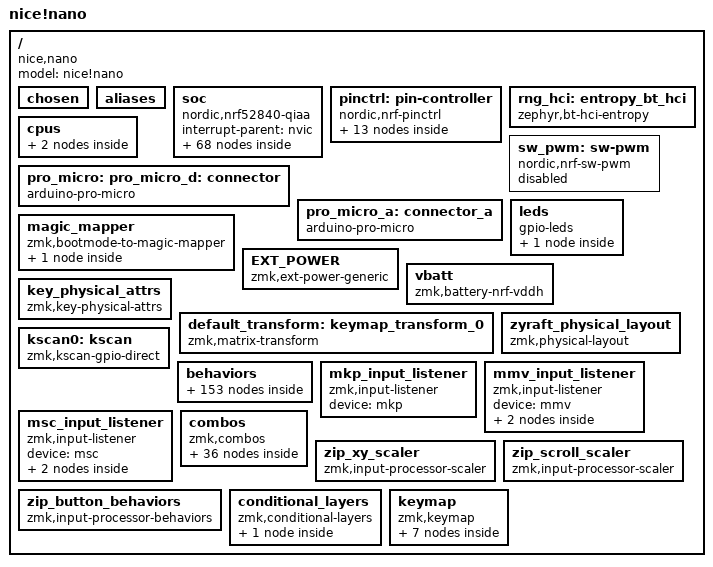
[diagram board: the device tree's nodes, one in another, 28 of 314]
/dts-v1/;

/ {
	#address-cells = < 0x1 >;
	#size-cells = < 0x1 >;
	model = "nice!nano";
	compatible = "nice,nano";
	chosen {
		zephyr,bt-hci = &bt_hci_controller;
		zephyr,entropy = &rng;
		zephyr,flash-controller = &flash_controller;
		zephyr,code-partition = &code_partition;
		zephyr,sram = &sram0;
		zephyr,flash = &flash0;
		zephyr,boot-mode = &boot_retention;
		zmk,magic-boot-mode = &adafruit_boot_retention;
		zmk,battery = &vbatt;
		zmk,physical-layout = &zyraft_physical_layout;
		zmk,kscan = &kscan0;
	};
	aliases {
	};
	soc {
		#address-cells = < 0x1 >;
		#size-cells = < 0x1 >;
		compatible = "nordic,nrf52840-qiaa", "nordic,nrf52840", "nordic,nrf52", "simple-bus";
		interrupt-parent = < &nvic >;
		ranges;
		nvic: interrupt-controller@e000e100 {
			#address-cells = < 0x1 >;
			compatible = "arm,v7m-nvic";
			reg = < 0xe000e100 0xc00 >;
			interrupt-controller;
			#interrupt-cells = < 0x2 >;
			arm,num-irq-priority-bits = < 0x3 >;
			phandle = < 0x1 >;
		};
		systick: timer@e000e010 {
			compatible = "arm,armv7m-systick";
			reg = < 0xe000e010 0x10 >;
			status = "disabled";
		};
		ficr: ficr@10000000 {
			compatible = "nordic,nrf-ficr";
			reg = < 0x10000000 0x1000 >;
			#nordic,ficr-cells = < 0x1 >;
			status = "okay";
		};
		uicr: uicr@10001000 {
			compatible = "nordic,nrf-uicr";
			reg = < 0x10001000 0x1000 >;
			status = "okay";
		};
		sram0: memory@20000000 {
			compatible = "mmio-sram";
			reg = < 0x20000000 0x40000 >;
		};
		clock: clock@40000000 {
			compatible = "nordic,nrf-clock";
			reg = < 0x40000000 0x1000 >;
			interrupts = < 0x0 0x1 >;
			status = "okay";
		};
		power: power@40000000 {
			compatible = "nordic,nrf-power";
			reg = < 0x40000000 0x1000 >;
			interrupts = < 0x0 0x1 >;
			status = "okay";
			#address-cells = < 0x1 >;
			#size-cells = < 0x1 >;
			gpregret1: gpregret1@4000051c {
				#address-cells = < 0x1 >;
				#size-cells = < 0x1 >;
				compatible = "nordic,nrf-gpregret";
				reg = < 0x4000051c 0x1 >;
				status = "okay";
				adafruit_boot_retention: retention@0 {
					compatible = "zephyr,retention";
					status = "okay";
					reg = < 0x0 0x1 >;
				};
			};
			gpregret2: gpregret2@40000520 {
				#address-cells = < 0x1 >;
				#size-cells = < 0x1 >;
				compatible = "nordic,nrf-gpregret";
				reg = < 0x40000520 0x1 >;
				status = "okay";
			};
			reg1: regulator@40000578 {
				compatible = "nordic,nrf5x-regulator";
				reg = < 0x40000578 0x1 >;
				regulator-name = "REG1";
				regulator-initial-mode = < 0x1 >;
			};
			reg0: regulator@40000580 {
				compatible = "nordic,nrf52x-regulator-hv";
				reg = < 0x40000580 0x1 >;
				regulator-name = "REG0";
				status = "okay";
			};
		};
		radio: radio@40001000 {
			compatible = "nordic,nrf-radio";
			reg = < 0x40001000 0x1000 >;
			interrupts = < 0x1 0x1 >;
			status = "okay";
			ieee802154-supported;
			ble-2mbps-supported;
			ble-coded-phy-supported;
			tx-high-power-supported;
			ieee802154: ieee802154 {
				compatible = "nordic,nrf-ieee802154";
				status = "disabled";
			};
			bt_hci_controller: bt_hci_controller {
				compatible = "zephyr,bt-hci-ll-sw-split";
				status = "okay";
			};
		};
		uart0: pro_micro_serial: uart@40002000 {
			compatible = "nordic,nrf-uarte";
			reg = < 0x40002000 0x1000 >;
			interrupts = < 0x2 0x1 >;
			status = "disabled";
			current-speed = < 0x1c200 >;
			pinctrl-0 = < &uart0_default >;
			pinctrl-1 = < &uart0_sleep >;
			pinctrl-names = "default", "sleep";
		};
		i2c0: pro_micro_i2c: i2c@40003000 {
			compatible = "nordic,nrf-twi";
			#address-cells = < 0x1 >;
			#size-cells = < 0x0 >;
			reg = < 0x40003000 0x1000 >;
			interrupts = < 0x3 0x1 >;
			easydma-maxcnt-bits = < 0x10 >;
			status = "disabled";
			zephyr,pm-device-runtime-auto;
			pinctrl-0 = < &i2c0_default >;
			pinctrl-1 = < &i2c0_sleep >;
			pinctrl-names = "default", "sleep";
		};
		spi0: spi@40003000 {
			compatible = "nordic,nrf-spim";
			#address-cells = < 0x1 >;
			#size-cells = < 0x0 >;
			reg = < 0x40003000 0x1000 >;
			interrupts = < 0x3 0x1 >;
			max-frequency = < 0x7a1200 >;
			easydma-maxcnt-bits = < 0x10 >;
			status = "disabled";
		};
		i2c1: i2c@40004000 {
			compatible = "nordic,nrf-twim";
			#address-cells = < 0x1 >;
			#size-cells = < 0x0 >;
			reg = < 0x40004000 0x1000 >;
			interrupts = < 0x4 0x1 >;
			easydma-maxcnt-bits = < 0x10 >;
			status = "disabled";
			zephyr,pm-device-runtime-auto;
		};
		spi1: pro_micro_spi: spi@40004000 {
			compatible = "nordic,nrf-spim";
			#address-cells = < 0x1 >;
			#size-cells = < 0x0 >;
			reg = < 0x40004000 0x1000 >;
			interrupts = < 0x4 0x1 >;
			max-frequency = < 0x7a1200 >;
			easydma-maxcnt-bits = < 0x10 >;
			status = "disabled";
			pinctrl-0 = < &spi1_default >;
			pinctrl-1 = < &spi1_sleep >;
			pinctrl-names = "default", "sleep";
		};
		nfct: nfct@40005000 {
			compatible = "nordic,nrf-nfct";
			reg = < 0x40005000 0x1000 >;
			interrupts = < 0x5 0x1 >;
			status = "disabled";
		};
		gpiote: gpiote0: gpiote@40006000 {
			compatible = "nordic,nrf-gpiote";
			reg = < 0x40006000 0x1000 >;
			interrupts = < 0x6 0x5 >;
			status = "okay";
			instance = < 0x0 >;
			phandle = < 0x8 >;
		};
		adc: adc@40007000 {
			compatible = "nordic,nrf-saadc";
			reg = < 0x40007000 0x1000 >;
			interrupts = < 0x7 0x1 >;
			status = "okay";
			#io-channel-cells = < 0x1 >;
			zephyr,pm-device-runtime-auto;
		};
		timer0: timer@40008000 {
			compatible = "nordic,nrf-timer";
			status = "disabled";
			reg = < 0x40008000 0x1000 >;
			cc-num = < 0x4 >;
			max-bit-width = < 0x20 >;
			interrupts = < 0x8 0x1 >;
			prescaler = < 0x0 >;
		};
		timer1: timer@40009000 {
			compatible = "nordic,nrf-timer";
			status = "disabled";
			reg = < 0x40009000 0x1000 >;
			cc-num = < 0x4 >;
			max-bit-width = < 0x20 >;
			interrupts = < 0x9 0x1 >;
			prescaler = < 0x0 >;
			phandle = < 0x9 >;
		};
		timer2: timer@4000a000 {
			compatible = "nordic,nrf-timer";
			status = "disabled";
			reg = < 0x4000a000 0x1000 >;
			cc-num = < 0x4 >;
			max-bit-width = < 0x20 >;
			interrupts = < 0xa 0x1 >;
			prescaler = < 0x0 >;
		};
		rtc0: rtc@4000b000 {
			compatible = "nordic,nrf-rtc";
			reg = < 0x4000b000 0x1000 >;
			cc-num = < 0x3 >;
			interrupts = < 0xb 0x1 >;
			status = "disabled";
			clock-frequency = < 0x8000 >;
			prescaler = < 0x1 >;
		};
		temp: temp@4000c000 {
			compatible = "nordic,nrf-temp";
			reg = < 0x4000c000 0x1000 >;
			interrupts = < 0xc 0x1 >;
			status = "okay";
		};
		rng: random@4000d000 {
			compatible = "nordic,nrf-rng";
			reg = < 0x4000d000 0x1000 >;
			interrupts = < 0xd 0x1 >;
			status = "okay";
		};
		ecb: ecb@4000e000 {
			compatible = "nordic,nrf-ecb";
			reg = < 0x4000e000 0x1000 >;
			interrupts = < 0xe 0x1 >;
			status = "okay";
		};
		ccm: ccm@4000f000 {
			compatible = "nordic,nrf-ccm";
			reg = < 0x4000f000 0x1000 >;
			interrupts = < 0xf 0x1 >;
			length-field-length-8-bits;
			status = "okay";
		};
		wdt: wdt0: watchdog@40010000 {
			compatible = "nordic,nrf-wdt";
			reg = < 0x40010000 0x1000 >;
			interrupts = < 0x10 0x1 >;
			status = "okay";
		};
		rtc1: rtc@40011000 {
			compatible = "nordic,nrf-rtc";
			reg = < 0x40011000 0x1000 >;
			cc-num = < 0x4 >;
			interrupts = < 0x11 0x1 >;
			status = "disabled";
			clock-frequency = < 0x8000 >;
			prescaler = < 0x1 >;
		};
		qdec: qdec0: qdec@40012000 {
			compatible = "nordic,nrf-qdec";
			reg = < 0x40012000 0x1000 >;
			interrupts = < 0x12 0x1 >;
			status = "disabled";
		};
		comp: comparator@40013000 {
			compatible = "nordic,nrf-comp";
			reg = < 0x40013000 0x1000 >;
			interrupts = < 0x13 0x1 >;
			status = "disabled";
		};
		egu0: swi0: egu@40014000 {
			compatible = "nordic,nrf-egu", "nordic,nrf-swi";
			reg = < 0x40014000 0x1000 >;
			interrupts = < 0x14 0x1 >;
			status = "okay";
		};
		egu1: swi1: egu@40015000 {
			compatible = "nordic,nrf-egu", "nordic,nrf-swi";
			reg = < 0x40015000 0x1000 >;
			interrupts = < 0x15 0x1 >;
			status = "okay";
		};
		egu2: swi2: egu@40016000 {
			compatible = "nordic,nrf-egu", "nordic,nrf-swi";
			reg = < 0x40016000 0x1000 >;
			interrupts = < 0x16 0x1 >;
			status = "okay";
		};
		egu3: swi3: egu@40017000 {
			compatible = "nordic,nrf-egu", "nordic,nrf-swi";
			reg = < 0x40017000 0x1000 >;
			interrupts = < 0x17 0x1 >;
			status = "okay";
		};
		egu4: swi4: egu@40018000 {
			compatible = "nordic,nrf-egu", "nordic,nrf-swi";
			reg = < 0x40018000 0x1000 >;
			interrupts = < 0x18 0x1 >;
			status = "okay";
		};
		egu5: swi5: egu@40019000 {
			compatible = "nordic,nrf-egu", "nordic,nrf-swi";
			reg = < 0x40019000 0x1000 >;
			interrupts = < 0x19 0x1 >;
			status = "okay";
		};
		timer3: timer@4001a000 {
			compatible = "nordic,nrf-timer";
			status = "disabled";
			reg = < 0x4001a000 0x1000 >;
			cc-num = < 0x6 >;
			max-bit-width = < 0x20 >;
			interrupts = < 0x1a 0x1 >;
			prescaler = < 0x0 >;
		};
		timer4: timer@4001b000 {
			compatible = "nordic,nrf-timer";
			status = "disabled";
			reg = < 0x4001b000 0x1000 >;
			cc-num = < 0x6 >;
			max-bit-width = < 0x20 >;
			interrupts = < 0x1b 0x1 >;
			prescaler = < 0x0 >;
		};
		pwm0: pwm@4001c000 {
			compatible = "nordic,nrf-pwm";
			reg = < 0x4001c000 0x1000 >;
			interrupts = < 0x1c 0x1 >;
			status = "disabled";
			#pwm-cells = < 0x3 >;
		};
		pdm0: pdm@4001d000 {
			compatible = "nordic,nrf-pdm";
			reg = < 0x4001d000 0x1000 >;
			interrupts = < 0x1d 0x1 >;
			status = "disabled";
		};
		acl: acl@4001e000 {
			compatible = "nordic,nrf-acl";
			reg = < 0x4001e000 0x1000 >;
			status = "okay";
		};
		flash_controller: flash-controller@4001e000 {
			compatible = "nordic,nrf52-flash-controller";
			reg = < 0x4001e000 0x1000 >;
			partial-erase;
			#address-cells = < 0x1 >;
			#size-cells = < 0x1 >;
			flash0: flash@0 {
				compatible = "soc-nv-flash";
				erase-block-size = < 0x1000 >;
				write-block-size = < 0x4 >;
				reg = < 0x0 0x100000 >;
				partitions {
					compatible = "fixed-partitions";
					#address-cells = < 0x1 >;
					#size-cells = < 0x1 >;
					sd_partition: partition@0 {
						reg = < 0x0 0x26000 >;
					};
					code_partition: partition@26000 {
						reg = < 0x26000 0xc6000 >;
					};
					storage_partition: partition@ec000 {
						reg = < 0xec000 0x8000 >;
					};
					boot_partition: partition@f4000 {
						reg = < 0xf4000 0xc000 >;
					};
				};
			};
		};
		ppi: ppi@4001f000 {
			compatible = "nordic,nrf-ppi";
			reg = < 0x4001f000 0x1000 >;
			status = "okay";
		};
		mwu: mwu@40020000 {
			compatible = "nordic,nrf-mwu";
			reg = < 0x40020000 0x1000 >;
			status = "okay";
		};
		pwm1: pwm@40021000 {
			compatible = "nordic,nrf-pwm";
			reg = < 0x40021000 0x1000 >;
			interrupts = < 0x21 0x1 >;
			status = "disabled";
			#pwm-cells = < 0x3 >;
		};
		pwm2: pwm@40022000 {
			compatible = "nordic,nrf-pwm";
			reg = < 0x40022000 0x1000 >;
			interrupts = < 0x22 0x1 >;
			status = "disabled";
			#pwm-cells = < 0x3 >;
		};
		spi2: spi@40023000 {
			compatible = "nordic,nrf-spim";
			#address-cells = < 0x1 >;
			#size-cells = < 0x0 >;
			reg = < 0x40023000 0x1000 >;
			interrupts = < 0x23 0x1 >;
			max-frequency = < 0x7a1200 >;
			easydma-maxcnt-bits = < 0x10 >;
			status = "disabled";
		};
		rtc2: rtc@40024000 {
			compatible = "nordic,nrf-rtc";
			reg = < 0x40024000 0x1000 >;
			cc-num = < 0x4 >;
			interrupts = < 0x24 0x1 >;
			status = "disabled";
			clock-frequency = < 0x8000 >;
			prescaler = < 0x1 >;
		};
		i2s0: i2s@40025000 {
			compatible = "nordic,nrf-i2s";
			#address-cells = < 0x1 >;
			#size-cells = < 0x0 >;
			reg = < 0x40025000 0x1000 >;
			interrupts = < 0x25 0x1 >;
			status = "disabled";
		};
		usbd: zephyr_udc0: usbd@40027000 {
			compatible = "nordic,nrf-usbd";
			reg = < 0x40027000 0x1000 >;
			interrupts = < 0x27 0x1 >;
			num-bidir-endpoints = < 0x1 >;
			num-in-endpoints = < 0x7 >;
			num-out-endpoints = < 0x7 >;
			num-isoin-endpoints = < 0x1 >;
			num-isoout-endpoints = < 0x1 >;
			status = "okay";
		};
		uart1: uart@40028000 {
			compatible = "nordic,nrf-uarte";
			reg = < 0x40028000 0x1000 >;
			interrupts = < 0x28 0x1 >;
			status = "disabled";
		};
		qspi: qspi@40029000 {
			compatible = "nordic,nrf-qspi";
			#address-cells = < 0x1 >;
			#size-cells = < 0x0 >;
			reg = < 0x40029000 0x1000 >, < 0x12000000 0x8000000 >;
			reg-names = "qspi", "qspi_mm";
			interrupts = < 0x29 0x1 >;
			status = "disabled";
		};
		pwm3: pwm@4002d000 {
			compatible = "nordic,nrf-pwm";
			reg = < 0x4002d000 0x1000 >;
			interrupts = < 0x2d 0x1 >;
			status = "disabled";
			#pwm-cells = < 0x3 >;
		};
		spi3: spi@4002f000 {
			compatible = "nordic,nrf-spim";
			#address-cells = < 0x1 >;
			#size-cells = < 0x0 >;
			reg = < 0x4002f000 0x1000 >;
			interrupts = < 0x2f 0x1 >;
			max-frequency = < 0x1e84800 >;
			easydma-maxcnt-bits = < 0x10 >;
			rx-delay-supported;
			rx-delay = < 0x2 >;
			status = "disabled";
		};
		gpio0: gpio@50000000 {
			compatible = "nordic,nrf-gpio";
			gpio-controller;
			reg = < 0x50000000 0x200 0x50000500 0x300 >;
			#gpio-cells = < 0x2 >;
			status = "okay";
			port = < 0x0 >;
			gpiote-instance = < &gpiote >;
			phandle = < 0xa >;
		};
		gpio1: gpio@50000300 {
			compatible = "nordic,nrf-gpio";
			gpio-controller;
			reg = < 0x50000300 0x200 0x50000800 0x300 >;
			#gpio-cells = < 0x2 >;
			ngpios = < 0x10 >;
			status = "okay";
			port = < 0x1 >;
			gpiote-instance = < &gpiote >;
			phandle = < 0xb >;
		};
		cryptocell: crypto@5002a000 {
			compatible = "nordic,cryptocell", "arm,cryptocell-310";
			reg = < 0x5002a000 0x1000 >, < 0x5002b000 0x1000 >;
			reg-names = "wrapper", "core";
			interrupts = < 0x2a 0x1 >;
			status = "disabled";
		};
	};
	pinctrl: pin-controller {
		compatible = "nordic,nrf-pinctrl";
		uart0_default: uart0_default {
			phandle = < 0x2 >;
			group1 {
				psels = < 0x1000008 >;
				bias-pull-up;
			};
			group2 {
				psels = < 0x6 >;
			};
		};
		uart0_sleep: uart0_sleep {
			phandle = < 0x3 >;
			group1 {
				psels = < 0x1000008 >, < 0x6 >;
				low-power-enable;
			};
		};
		i2c0_default: i2c0_default {
			phandle = < 0x4 >;
			group1 {
				psels = < 0xc000011 >, < 0xb000014 >;
			};
		};
		i2c0_sleep: i2c0_sleep {
			phandle = < 0x5 >;
			group1 {
				psels = < 0xc000011 >, < 0xb000014 >;
				low-power-enable;
			};
		};
		spi1_default: spi1_default {
			phandle = < 0x6 >;
			group1 {
				psels = < 0x400002d >, < 0x500000a >, < 0x600002b >;
			};
		};
		spi1_sleep: spi1_sleep {
			phandle = < 0x7 >;
			group1 {
				psels = < 0x400002d >, < 0x500000a >, < 0x600002b >;
				low-power-enable;
			};
		};
	};
	rng_hci: entropy_bt_hci {
		compatible = "zephyr,bt-hci-entropy";
		status = "okay";
	};
	sw_pwm: sw-pwm {
		compatible = "nordic,nrf-sw-pwm";
		status = "disabled";
		generator = < &timer1 >;
		clock-prescaler = < 0x0 >;
		#pwm-cells = < 0x3 >;
	};
	cpus {
		#address-cells = < 0x1 >;
		#size-cells = < 0x0 >;
		cpu@0 {
			device_type = "cpu";
			compatible = "arm,cortex-m4f";
			reg = < 0x0 >;
			#address-cells = < 0x1 >;
			#size-cells = < 0x1 >;
			itm: itm@e0000000 {
				compatible = "arm,armv7m-itm";
				reg = < 0xe0000000 0x1000 >;
				swo-ref-frequency = < 0x1e84800 >;
			};
		};
	};
	pro_micro: pro_micro_d: connector {
		compatible = "arduino-pro-micro";
		#gpio-cells = < 0x2 >;
		gpio-map-mask = < 0xffffffff 0xffffffc0 >;
		gpio-map-pass-thru = < 0x0 0x3f >;
		gpio-map = < 0x0 0x0 &gpio0 0x8 0x0 >, < 0x1 0x0 &gpio0 0x6 0x0 >, < 0x2 0x0 &gpio0 0x11 0x0 >, < 0x3 0x0 &gpio0 0x14 0x0 >, < 0x4 0x0 &gpio0 0x16 0x0 >, < 0x5 0x0 &gpio0 0x18 0x0 >, < 0x6 0x0 &gpio1 0x0 0x0 >, < 0x7 0x0 &gpio0 0xb 0x0 >, < 0x8 0x0 &gpio1 0x4 0x0 >, < 0x9 0x0 &gpio1 0x6 0x0 >, < 0xa 0x0 &gpio0 0x9 0x0 >, < 0x10 0x0 &gpio0 0xa 0x0 >, < 0xe 0x0 &gpio1 0xb 0x0 >, < 0xf 0x0 &gpio1 0xd 0x0 >, < 0x12 0x0 &gpio1 0xf 0x0 >, < 0x13 0x0 &gpio0 0x2 0x0 >, < 0x14 0x0 &gpio0 0x1d 0x0 >, < 0x15 0x0 &gpio0 0x1f 0x0 >;
		phandle = < 0xe >;
	};
	pro_micro_a: connector_a {
		compatible = "arduino-pro-micro";
		#gpio-cells = < 0x2 >;
		gpio-map-mask = < 0xffffffff 0xffffffc0 >;
		gpio-map-pass-thru = < 0x0 0x3f >;
		gpio-map = < 0x0 0x0 &gpio1 0xf 0x0 >, < 0x1 0x0 &gpio0 0x2 0x0 >, < 0x2 0x0 &gpio0 0x1d 0x0 >, < 0x3 0x0 &gpio0 0x1f 0x0 >, < 0x6 0x0 &gpio0 0x16 0x0 >, < 0x7 0x0 &gpio1 0x0 0x0 >, < 0x8 0x0 &gpio1 0x4 0x0 >, < 0x9 0x0 &gpio1 0x6 0x0 >, < 0xa 0x0 &gpio0 0x9 0x0 >;
	};
	leds {
		compatible = "gpio-leds";
		blue_led: led_0 {
			gpios = < &gpio0 0xf 0x0 >;
		};
	};
	magic_mapper {
		compatible = "zmk,bootmode-to-magic-mapper";
		status = "okay";
		#address-cells = < 0x1 >;
		#size-cells = < 0x1 >;
		boot_retention: retention@0 {
			compatible = "zephyr,retention";
			status = "okay";
			reg = < 0x0 0x1 >;
		};
	};
	EXT_POWER {
		compatible = "zmk,ext-power-generic";
		control-gpios = < &gpio0 0xd 0x0 >;
		init-delay-ms = < 0x32 >;
	};
	vbatt: vbatt {
		compatible = "zmk,battery-nrf-vddh";
	};
	key_physical_attrs: key_physical_attrs {
		compatible = "zmk,key-physical-attrs";
		#key-cells = < 0x7 >;
		phandle = < 0xd >;
	};
	default_transform: keymap_transform_0 {
		compatible = "zmk,matrix-transform";
		columns = < 0x22 >;
		rows = < 0x1 >;
		map = < 0x0 0x1 0x2 0x3 0x4 0x15 0x14 0x13 0x12 0x11 0x5 0x6 0x7 0x8 0x9 0x1a 0x19 0x18 0x17 0x16 0xa 0xb 0xc 0xd 0xe 0x1f 0x1e 0x1d 0x1c 0x1b 0xf 0x10 0x21 0x20 >;
		phandle = < 0xc >;
	};
	zyraft_physical_layout: zyraft_physical_layout {
		compatible = "zmk,physical-layout";
		display-name = "Zyra FT";
		transform = < &default_transform >;
		keys = < &key_physical_attrs 0x64 0x64 0x0 0x5f 0x0 0x0 0x0 >, < &key_physical_attrs 0x64 0x64 0x64 0x20 0x0 0x0 0x0 >, < &key_physical_attrs 0x64 0x64 0xc8 0x0 0x0 0x0 0x0 >, < &key_physical_attrs 0x64 0x64 0x12c 0x1c 0x0 0x0 0x0 >, < &key_physical_attrs 0x64 0x64 0x190 0x2a 0x0 0x0 0x0 >, < &key_physical_attrs 0x64 0x64 0x2bc 0x2a 0x0 0x0 0x0 >, < &key_physical_attrs 0x64 0x64 0x320 0x1c 0x0 0x0 0x0 >, < &key_physical_attrs 0x64 0x64 0x384 0x0 0x0 0x0 0x0 >, < &key_physical_attrs 0x64 0x64 0x3e8 0x20 0x0 0x0 0x0 >, < &key_physical_attrs 0x64 0x64 0x44c 0x5f 0x0 0x0 0x0 >, < &key_physical_attrs 0x64 0x64 0x0 0xc3 0x0 0x0 0x0 >, < &key_physical_attrs 0x64 0x64 0x64 0x84 0x0 0x0 0x0 >, < &key_physical_attrs 0x64 0x64 0xc8 0x64 0x0 0x0 0x0 >, < &key_physical_attrs 0x64 0x64 0x12c 0x80 0x0 0x0 0x0 >, < &key_physical_attrs 0x64 0x64 0x190 0x8e 0x0 0x0 0x0 >, < &key_physical_attrs 0x64 0x64 0x2bc 0x8e 0x0 0x0 0x0 >, < &key_physical_attrs 0x64 0x64 0x320 0x80 0x0 0x0 0x0 >, < &key_physical_attrs 0x64 0x64 0x384 0x64 0x0 0x0 0x0 >, < &key_physical_attrs 0x64 0x64 0x3e8 0x84 0x0 0x0 0x0 >, < &key_physical_attrs 0x64 0x64 0x44c 0xc3 0x0 0x0 0x0 >, < &key_physical_attrs 0x64 0x64 0x0 0x127 0x0 0x0 0x0 >, < &key_physical_attrs 0x64 0x64 0x64 0xe8 0x0 0x0 0x0 >, < &key_physical_attrs 0x64 0x64 0xc8 0xc8 0x0 0x0 0x0 >, < &key_physical_attrs 0x64 0x64 0x12c 0xe4 0x0 0x0 0x0 >, < &key_physical_attrs 0x64 0x64 0x190 0xf2 0x0 0x0 0x0 >, < &key_physical_attrs 0x64 0x64 0x2bc 0xf2 0x0 0x0 0x0 >, < &key_physical_attrs 0x64 0x64 0x320 0xe4 0x0 0x0 0x0 >, < &key_physical_attrs 0x64 0x64 0x384 0xc8 0x0 0x0 0x0 >, < &key_physical_attrs 0x64 0x64 0x3e8 0xe8 0x0 0x0 0x0 >, < &key_physical_attrs 0x64 0x64 0x44c 0x127 0x0 0x0 0x0 >, < &key_physical_attrs 0x64 0x64 0x12c 0x156 0x0 0x0 0x0 >, < &key_physical_attrs 0x64 0x64 0x190 0x181 0x0 0x0 0x0 >, < &key_physical_attrs 0x64 0x64 0x2bc 0x181 0x0 0x0 0x0 >, < &key_physical_attrs 0x64 0x64 0x320 0x156 0x0 0x0 0x0 >;
	};
	kscan0: kscan {
		compatible = "zmk,kscan-gpio-direct";
		wakeup-source;
		input-gpios = < &pro_micro 0x7 0x11 >, < &pro_micro 0x12 0x11 >, < &pro_micro 0x13 0x11 >, < &pro_micro 0x14 0x11 >, < &pro_micro 0x15 0x11 >, < &pro_micro 0xf 0x11 >, < &pro_micro 0xe 0x11 >, < &pro_micro 0x10 0x11 >, < &pro_micro 0xa 0x11 >, < &pro_micro 0x1 0x11 >, < &pro_micro 0x2 0x11 >, < &pro_micro 0x3 0x11 >, < &pro_micro 0x4 0x11 >, < &pro_micro 0x5 0x11 >, < &pro_micro 0x6 0x11 >, < &pro_micro 0x8 0x11 >, < &pro_micro 0x9 0x11 >;
	};
	behaviors {
		os_sel: os_selector {
			compatible = "zmk,behavior-os-selector";
			#binding-cells = < 0x1 >;
			phandle = < 0x2a >;
		};
		ok_cut: os_key_cut {
			compatible = "zmk,behavior-os-key";
			#binding-cells = < 0x0 >;
			bindings = < &kp 0x107001b >, < &kp 0x807001b >, < &kp 0x107001b >;
			phandle = < 0x38 >;
		};
		ok_copy: os_key_copy {
			compatible = "zmk,behavior-os-key";
			#binding-cells = < 0x0 >;
			bindings = < &kp 0x1070006 >, < &kp 0x8070006 >, < &kp 0x1070006 >;
			phandle = < 0x39 >;
		};
		ok_paste: os_key_paste {
			compatible = "zmk,behavior-os-key";
			#binding-cells = < 0x0 >;
			bindings = < &kp 0x1070019 >, < &kp 0x8070019 >, < &kp 0x1070019 >;
			phandle = < 0x3a >;
		};
		ok_undo: os_key_undo {
			compatible = "zmk,behavior-os-key";
			#binding-cells = < 0x0 >;
			bindings = < &kp 0x107001d >, < &kp 0x807001d >, < &kp 0x107001d >;
			phandle = < 0x4a >;
		};
		ok_redo: os_key_redo {
			compatible = "zmk,behavior-os-key";
			#binding-cells = < 0x0 >;
			bindings = < &kp 0x107001c >, < &kp 0xa07001d >, < &kp 0x307001d >;
			phandle = < 0x4b >;
		};
		ok_sel_all: os_key_select_all {
			compatible = "zmk,behavior-os-key";
			#binding-cells = < 0x0 >;
			bindings = < &kp 0x1070004 >, < &kp 0x8070004 >, < &kp 0x1070004 >;
		};
		ok_find: os_key_find {
			compatible = "zmk,behavior-os-key";
			#binding-cells = < 0x0 >;
			bindings = < &kp 0x1070009 >, < &kp 0x8070009 >, < &kp 0x1070009 >;
		};
		ok_find_replace: os_key_find_replace {
			compatible = "zmk,behavior-os-key";
			#binding-cells = < 0x0 >;
			bindings = < &kp 0x107000b >, < &kp 0x807000b >, < &kp 0x107000b >;
		};
		ok_bold: os_key_bold {
			compatible = "zmk,behavior-os-key";
			#binding-cells = < 0x0 >;
			bindings = < &kp 0x1070005 >, < &kp 0x8070005 >, < &kp 0x1070005 >;
		};
		ok_italic: os_key_italic {
			compatible = "zmk,behavior-os-key";
			#binding-cells = < 0x0 >;
			bindings = < &kp 0x107000c >, < &kp 0x807000c >, < &kp 0x107000c >;
		};
		ok_underline: os_key_underline {
			compatible = "zmk,behavior-os-key";
			#binding-cells = < 0x0 >;
			bindings = < &kp 0x1070018 >, < &kp 0x8070018 >, < &kp 0x1070018 >;
		};
		ok_new_win: os_key_new_window {
			compatible = "zmk,behavior-os-key";
			#binding-cells = < 0x0 >;
			bindings = < &kp 0x1070011 >, < &kp 0x8070011 >, < &kp 0x1070011 >;
		};
		ok_new_tab: os_key_new_tab {
			compatible = "zmk,behavior-os-key";
			#binding-cells = < 0x0 >;
			bindings = < &kp 0x1070017 >, < &kp 0x8070017 >, < &kp 0x1070017 >;
		};
		ok_close: os_key_close {
			compatible = "zmk,behavior-os-key";
			#binding-cells = < 0x0 >;
			bindings = < &kp 0x107001a >, < &kp 0x807001a >, < &kp 0x107001a >;
		};
		ok_quit: os_key_quit {
			compatible = "zmk,behavior-os-key";
			#binding-cells = < 0x0 >;
			bindings = < &kp 0x407003d >, < &kp 0x8070014 >, < &kp 0x407003d >;
		};
		ok_reopen_tab: os_key_reopen_tab {
			compatible = "zmk,behavior-os-key";
			#binding-cells = < 0x0 >;
			bindings = < &kp 0x3070017 >, < &kp 0xa070017 >, < &kp 0x3070017 >;
		};
		ok_open: os_key_open {
			compatible = "zmk,behavior-os-key";
			#binding-cells = < 0x0 >;
			bindings = < &kp 0x1070012 >, < &kp 0x8070012 >, < &kp 0x1070012 >;
		};
		ok_save: os_key_save {
			compatible = "zmk,behavior-os-key";
			#binding-cells = < 0x0 >;
			bindings = < &kp 0x1070016 >, < &kp 0x8070016 >, < &kp 0x1070016 >;
		};
		ok_save_as: os_key_save_as {
			compatible = "zmk,behavior-os-key";
			#binding-cells = < 0x0 >;
			bindings = < &kp 0x3070016 >, < &kp 0xa070016 >, < &kp 0x3070016 >;
		};
		ok_print: os_key_print {
			compatible = "zmk,behavior-os-key";
			#binding-cells = < 0x0 >;
			bindings = < &kp 0x1070013 >, < &kp 0x8070013 >, < &kp 0x1070013 >;
		};
		ok_zoom_in: os_key_zoom_in {
			compatible = "zmk,behavior-os-key";
			#binding-cells = < 0x0 >;
			bindings = < &kp 0x107002e >, < &kp 0x807002e >, < &kp 0x107002e >;
		};
		ok_zoom_out: os_key_zoom_out {
			compatible = "zmk,behavior-os-key";
			#binding-cells = < 0x0 >;
			bindings = < &kp 0x107002d >, < &kp 0x807002d >, < &kp 0x107002d >;
		};
		ok_zoom_reset: os_key_zoom_reset {
			compatible = "zmk,behavior-os-key";
			#binding-cells = < 0x0 >;
			bindings = < &kp 0x1070027 >, < &kp 0x8070027 >, < &kp 0x1070027 >;
		};
		ok_prev_word: os_key_prev_word {
			compatible = "zmk,behavior-os-key";
			#binding-cells = < 0x0 >;
			bindings = < &kp 0x1070050 >, < &kp 0x4070050 >, < &kp 0x1070050 >;
		};
		ok_next_word: os_key_next_word {
			compatible = "zmk,behavior-os-key";
			#binding-cells = < 0x0 >;
			bindings = < &kp 0x107004f >, < &kp 0x407004f >, < &kp 0x107004f >;
		};
		ok_line_start: os_key_line_start {
			compatible = "zmk,behavior-os-key";
			#binding-cells = < 0x0 >;
			bindings = < &kp 0x7004a >, < &kp 0x8070050 >, < &kp 0x7004a >;
		};
		ok_line_end: os_key_line_end {
			compatible = "zmk,behavior-os-key";
			#binding-cells = < 0x0 >;
			bindings = < &kp 0x7004d >, < &kp 0x807004f >, < &kp 0x7004d >;
		};
		ok_doc_start: os_key_doc_start {
			compatible = "zmk,behavior-os-key";
			#binding-cells = < 0x0 >;
			bindings = < &kp 0x107004a >, < &kp 0x8070052 >, < &kp 0x107004a >;
		};
		ok_doc_end: os_key_doc_end {
			compatible = "zmk,behavior-os-key";
			#binding-cells = < 0x0 >;
			bindings = < &kp 0x107004d >, < &kp 0x8070051 >, < &kp 0x107004d >;
		};
		ok_sel_prev_word: os_key_sel_prev_word {
			compatible = "zmk,behavior-os-key";
			#binding-cells = < 0x0 >;
			bindings = < &kp 0x3070050 >, < &kp 0x6070050 >, < &kp 0x3070050 >;
		};
		ok_sel_next_word: os_key_sel_next_word {
			compatible = "zmk,behavior-os-key";
			#binding-cells = < 0x0 >;
			bindings = < &kp 0x307004f >, < &kp 0x607004f >, < &kp 0x307004f >;
		};
		ok_sel_line_start: os_key_sel_line_start {
			compatible = "zmk,behavior-os-key";
			#binding-cells = < 0x0 >;
			bindings = < &kp 0x207004a >, < &kp 0xa070050 >, < &kp 0x207004a >;
		};
		ok_sel_line_end: os_key_sel_line_end {
			compatible = "zmk,behavior-os-key";
			#binding-cells = < 0x0 >;
			bindings = < &kp 0x207004d >, < &kp 0xa07004f >, < &kp 0x207004d >;
		};
		ok_sel_doc_start: os_key_sel_doc_start {
			compatible = "zmk,behavior-os-key";
			#binding-cells = < 0x0 >;
			bindings = < &kp 0x307004a >, < &kp 0xa070052 >, < &kp 0x307004a >;
		};
		ok_sel_doc_end: os_key_sel_doc_end {
			compatible = "zmk,behavior-os-key";
			#binding-cells = < 0x0 >;
			bindings = < &kp 0x307004d >, < &kp 0xa070051 >, < &kp 0x307004d >;
		};
		ok_ltm: os_layer_mod {
			compatible = "zmk,behavior-os-layer-mod";
			#binding-cells = < 0x2 >;
			tapping-term-ms = < 0xc8 >;
			bindings = < &kp 0x700e2 >, < &kp 0x700e3 >, < &kp 0x700e3 >;
		};
		ok_next_app: os_key_next_app {
			compatible = "zmk,behavior-os-key";
			#binding-cells = < 0x0 >;
			bindings = < &kp 0x407002b >, < &kp 0x807002b >, < &kp 0x807002b >;
		};
		ok_prev_app: os_key_prev_app {
			compatible = "zmk,behavior-os-key";
			#binding-cells = < 0x0 >;
			bindings = < &kp 0x607002b >, < &kp 0xa07002b >, < &kp 0xa07002b >;
		};
		ok_next_tab: os_key_next_tab {
			compatible = "zmk,behavior-os-key";
			#binding-cells = < 0x0 >;
			bindings = < &kp 0x3070030 >, < &kp 0xa070030 >, < &kp 0x107004e >;
		};
		ok_prev_tab: os_key_prev_tab {
			compatible = "zmk,behavior-os-key";
			#binding-cells = < 0x0 >;
			bindings = < &kp 0x307002f >, < &kp 0xa07002f >, < &kp 0x107004b >;
		};
		ok_mission_ctrl: os_key_mission_control {
			compatible = "zmk,behavior-os-key";
			#binding-cells = < 0x0 >;
			bindings = < &kp 0x807002b >, < &kp 0x1070052 >, < &kp 0x700e3 >;
		};
		ok_desktop: os_key_desktop {
			compatible = "zmk,behavior-os-key";
			#binding-cells = < 0x0 >;
			bindings = < &kp 0x8070007 >, < &kp 0x9070007 >, < &kp 0x8070007 >;
		};
		ok_lock: os_key_lock {
			compatible = "zmk,behavior-os-key";
			#binding-cells = < 0x0 >;
			bindings = < &kp 0x807000f >, < &kp 0x9070014 >, < &kp 0x807000f >;
		};
		ok_force_quit: os_key_force_quit {
			compatible = "zmk,behavior-os-key";
			#binding-cells = < 0x0 >;
			bindings = < &kp 0x3070029 >, < &kp 0xc070029 >, < &kp 0x1070029 >;
		};
		kp: key_press {
			compatible = "zmk,behavior-key-press";
			#binding-cells = < 0x1 >;
			display-name = "Key Press";
			phandle = < 0xf >;
		};
		kt: key_toggle {
			compatible = "zmk,behavior-key-toggle";
			#binding-cells = < 0x1 >;
			display-name = "Key Toggle";
			phandle = < 0x2b >;
		};
		trans: transparent {
			compatible = "zmk,behavior-transparent";
			#binding-cells = < 0x0 >;
			display-name = "Transparent";
			phandle = < 0x46 >;
		};
		none: none {
			compatible = "zmk,behavior-none";
			#binding-cells = < 0x0 >;
			display-name = "None";
			phandle = < 0x24 >;
		};
		mt: mod_tap {
			compatible = "zmk,behavior-hold-tap";
			#binding-cells = < 0x2 >;
			flavor = "tap-preferred";
			tapping-term-ms = < 0xdc >;
			bindings = < &kp >, < &kp >;
			display-name = "Mod-Tap";
			quick-tap-ms = < 0xdc >;
			hold-trigger-key-positions = < 0x0 >;
			phandle = < 0x45 >;
		};
		lt: layer_tap {
			compatible = "zmk,behavior-hold-tap";
			#binding-cells = < 0x2 >;
			flavor = "balanced";
			tapping-term-ms = < 0xc8 >;
			bindings = < &mo >, < &kp >;
			display-name = "Layer-Tap";
			quick-tap-ms = < 0xaf >;
			phandle = < 0x3e >;
		};
		sk: sticky_key {
			compatible = "zmk,behavior-sticky-key";
			#binding-cells = < 0x1 >;
			release-after-ms = < 0x384 >;
			bindings = < &kp >;
			ignore-modifiers;
			display-name = "Sticky Key";
			quick-release;
			phandle = < 0x1e >;
		};
		sl: sticky_layer {
			compatible = "zmk,behavior-sticky-key";
			#binding-cells = < 0x1 >;
			release-after-ms = < 0x3e8 >;
			bindings = < &mo >;
			quick-release;
			display-name = "Sticky Layer";
			ignore-modifiers;
			phandle = < 0x22 >;
		};
		mo: momentary_layer {
			compatible = "zmk,behavior-momentary-layer";
			#binding-cells = < 0x1 >;
			display-name = "Momentary Layer";
			phandle = < 0x10 >;
		};
		tog: toggle_layer {
			compatible = "zmk,behavior-toggle-layer";
			#binding-cells = < 0x1 >;
			display-name = "Toggle Layer";
			locking;
			phandle = < 0x23 >;
		};
		sys_reset: sysreset {
			compatible = "zmk,behavior-reset";
			#binding-cells = < 0x0 >;
			display-name = "Reset";
			phandle = < 0x17 >;
		};
		bootloader: bootload {
			compatible = "zmk,behavior-reset";
			type = < 0x57 >;
			bootloader;
			#binding-cells = < 0x0 >;
			display-name = "Bootloader";
			phandle = < 0x18 >;
		};
		rgb_ug: rgb_ug {
			compatible = "zmk,behavior-rgb-underglow";
			#binding-cells = < 0x2 >;
			display-name = "Underglow";
		};
		bt: bluetooth {
			compatible = "zmk,behavior-bluetooth";
			#binding-cells = < 0x2 >;
			display-name = "Bluetooth";
			phandle = < 0x29 >;
		};
		ext_power: extpower {
			compatible = "zmk,behavior-ext-power";
			#binding-cells = < 0x1 >;
			display-name = "External Power";
		};
		out: outputs {
			compatible = "zmk,behavior-outputs";
			#binding-cells = < 0x1 >;
			display-name = "Output Selection";
			phandle = < 0x16 >;
		};
		caps_word: caps_word {
			compatible = "zmk,behavior-caps-word";
			#binding-cells = < 0x0 >;
			continue-list = < 0x207002d 0x7002a 0x7004c >;
			display-name = "Caps Word";
			phandle = < 0x1d >;
		};
		key_repeat: key_repeat {
			compatible = "zmk,behavior-key-repeat";
			#binding-cells = < 0x0 >;
			usage-pages = < 0x7 >;
			display-name = "Key Repeat";
			phandle = < 0x1f >;
		};
		macro_tap: macro_tap {
			compatible = "zmk,macro-control-mode-tap";
			#binding-cells = < 0x0 >;
		};
		macro_press: macro_press {
			compatible = "zmk,macro-control-mode-press";
			#binding-cells = < 0x0 >;
		};
		macro_release: macro_release {
			compatible = "zmk,macro-control-mode-release";
			#binding-cells = < 0x0 >;
		};
		macro_tap_time: macro_tap_time {
			compatible = "zmk,macro-control-tap-time";
			#binding-cells = < 0x1 >;
		};
		macro_wait_time: macro_wait_time {
			compatible = "zmk,macro-control-wait-time";
			#binding-cells = < 0x1 >;
		};
		macro_pause_for_release: macro_pause_for_release {
			compatible = "zmk,macro-pause-for-release";
			#binding-cells = < 0x0 >;
		};
		macro_param_1to1: macro_param_1to1 {
			compatible = "zmk,macro-param-1to1";
			#binding-cells = < 0x0 >;
		};
		macro_param_1to2: macro_param_1to2 {
			compatible = "zmk,macro-param-1to2";
			#binding-cells = < 0x0 >;
		};
		macro_param_2to1: macro_param_2to1 {
			compatible = "zmk,macro-param-2to1";
			#binding-cells = < 0x0 >;
		};
		macro_param_2to2: macro_param_2to2 {
			compatible = "zmk,macro-param-2to2";
			#binding-cells = < 0x0 >;
		};
		studio_unlock: studio_unlock {
			compatible = "zmk,behavior-studio-unlock";
			#binding-cells = < 0x0 >;
			display-name = "Studio Unlock";
			phandle = < 0x4c >;
		};
		mkp: mouse_key_press {
			compatible = "zmk,behavior-mouse-key-press";
			#binding-cells = < 0x1 >;
			display-name = "Mouse Key Press";
			phandle = < 0x2f >;
		};
		mmv: mouse_move {
			compatible = "zmk,behavior-input-two-axis";
			#binding-cells = < 0x1 >;
			x-input-code = < 0x0 >;
			y-input-code = < 0x1 >;
			time-to-max-speed-ms = < 0x1f4 >;
			acceleration-exponent = < 0x1 >;
			delay-ms = < 0x0 >;
			phandle = < 0x30 >;
		};
		msc: mouse_scroll {
			compatible = "zmk,behavior-input-two-axis";
			#binding-cells = < 0x1 >;
			x-input-code = < 0x6 >;
			y-input-code = < 0x8 >;
			time-to-max-speed-ms = < 0x12c >;
			acceleration-exponent = < 0x0 >;
			delay-ms = < 0x0 >;
			phandle = < 0x32 >;
		};
		num_word: num_word {
			compatible = "zmk,behavior-auto-layer";
			#binding-cells = < 0x1 >;
			continue-list = < 0x7002a 0x7004c 0x70037 0x70036 0x207002e 0x7002d 0x2070025 0x70038 0x7002e >;
			ignore-numbers;
			phandle = < 0x21 >;
		};
		mask_mods: mask_mods {
			compatible = "zmk,behavior-mask-mods";
			#binding-cells = < 0x1 >;
			display-name = "Mask Mods";
		};
		uc: unicode {
			compatible = "zmk,behavior-unicode";
			#binding-cells = < 0x2 >;
			display-name = "Unicode input";
			default-mode = < 0x3 >;
			phandle = < 0x15 >;
		};
		hml: hml {
			compatible = "zmk,behavior-hold-tap";
			#binding-cells = < 0x2 >;
			bindings = < &kp >, < &kp >;
			flavor = "balanced";
			tapping-term-ms = < 0x118 >;
			quick-tap-ms = < 0xaf >;
			require-prior-idle-ms = < 0x96 >;
			hold-trigger-on-release;
			hold-trigger-key-positions = < 0x5 0x6 0x7 0x8 0x9 0xf 0x10 0x11 0x12 0x13 0x19 0x1a 0x1b 0x1c 0x1d 0x1e 0x1f 0x20 0x21 >;
			phandle = < 0x35 >;
		};
		hmr: hmr {
			compatible = "zmk,behavior-hold-tap";
			#binding-cells = < 0x2 >;
			bindings = < &kp >, < &kp >;
			flavor = "balanced";
			tapping-term-ms = < 0x118 >;
			quick-tap-ms = < 0xaf >;
			require-prior-idle-ms = < 0x96 >;
			hold-trigger-on-release;
			hold-trigger-key-positions = < 0x4 0x3 0x2 0x1 0x0 0xe 0xd 0xc 0xb 0xa 0x18 0x17 0x16 0x15 0x14 0x1e 0x1f 0x20 0x21 >;
			phandle = < 0x40 >;
		};
		hm_combo_ldr: hm_combo_ldr {
			compatible = "zmk,behavior-hold-tap";
			#binding-cells = < 0x2 >;
			bindings = < &kp >, < &leader >;
			flavor = "balanced";
			tapping-term-ms = < 0x118 >;
			quick-tap-ms = < 0xaf >;
			require-prior-idle-ms = < 0x96 >;
			hold-trigger-on-release;
			hold-trigger-key-positions = < 0x5 0x6 0x7 0x8 0x9 0xf 0x10 0x11 0x12 0x13 0x19 0x1a 0x1b 0x1c 0x1d 0x1e 0x1f 0x20 0x21 >;
			phandle = < 0x36 >;
		};
		hm_combo_ldrsh: hm_combo_ldrsh {
			compatible = "zmk,behavior-hold-tap";
			#binding-cells = < 0x2 >;
			bindings = < &kp >, < &leader_sft >;
			flavor = "balanced";
			tapping-term-ms = < 0x118 >;
			quick-tap-ms = < 0xaf >;
			require-prior-idle-ms = < 0x96 >;
			hold-trigger-on-release;
			hold-trigger-key-positions = < 0x5 0x6 0x7 0x8 0x9 0xf 0x10 0x11 0x12 0x13 0x19 0x1a 0x1b 0x1c 0x1d 0x1e 0x1f 0x20 0x21 >;
			phandle = < 0x37 >;
		};
		hm_combo_lpar: hm_combo_lpar {
			compatible = "zmk,behavior-hold-tap";
			#binding-cells = < 0x2 >;
			bindings = < &kp >, < &lpar_lt >;
			flavor = "balanced";
			tapping-term-ms = < 0x118 >;
			quick-tap-ms = < 0xaf >;
			require-prior-idle-ms = < 0x96 >;
			hold-trigger-on-release;
			hold-trigger-key-positions = < 0x4 0x3 0x2 0x1 0x0 0xe 0xd 0xc 0xb 0xa 0x18 0x17 0x16 0x15 0x14 0x1e 0x1f 0x20 0x21 >;
			phandle = < 0x3b >;
		};
		hm_combo_rpar: hm_combo_rpar {
			compatible = "zmk,behavior-hold-tap";
			#binding-cells = < 0x2 >;
			bindings = < &kp >, < &rpar_gt >;
			flavor = "balanced";
			tapping-term-ms = < 0x118 >;
			quick-tap-ms = < 0xaf >;
			require-prior-idle-ms = < 0x96 >;
			hold-trigger-on-release;
			hold-trigger-key-positions = < 0x4 0x3 0x2 0x1 0x0 0xe 0xd 0xc 0xb 0xa 0x18 0x17 0x16 0x15 0x14 0x1e 0x1f 0x20 0x21 >;
			phandle = < 0x3c >;
		};
		leader: leader {
			compatible = "zmk,behavior-leader-key";
			#binding-cells = < 0x0 >;
			ignore-keys = < 0x700e1 0x700e5 >;
			phandle = < 0x11 >;
			leader_sequence_de_ae {
				bindings = < &uc 0xe4 0xc4 >;
				sequence = < 0x70004 >;
			};
			leader_sequence_de_oe {
				bindings = < &uc 0xf6 0xd6 >;
				sequence = < 0x70012 >;
			};
			leader_sequence_de_ue {
				bindings = < &uc 0xfc 0xdc >;
				sequence = < 0x70018 >;
			};
			leader_sequence_de_eszett {
				bindings = < &uc 0xdf 0x1e9e >;
				sequence = < 0x70016 >;
			};
			leader_sequence_el_alpha {
				bindings = < &uc 0x3b1 0x391 >;
				sequence = < 0x70008 0x70004 >;
			};
			leader_sequence_el_beta {
				bindings = < &uc 0x3b2 0x392 >;
				sequence = < 0x70008 0x70005 >;
			};
			leader_sequence_el_gamma {
				bindings = < &uc 0x3b3 0x393 >;
				sequence = < 0x70008 0x7000a >;
			};
			leader_sequence_el_delta {
				bindings = < &uc 0x3b4 0x394 >;
				sequence = < 0x70008 0x70007 >;
			};
			leader_sequence_el_epsilon {
				bindings = < &uc 0x3b5 0x395 >;
				sequence = < 0x70008 0x70008 >;
			};
			leader_sequence_el_zeta {
				bindings = < &uc 0x3b6 0x396 >;
				sequence = < 0x70008 0x7001d >;
			};
			leader_sequence_el_eta {
				bindings = < &uc 0x3b7 0x397 >;
				sequence = < 0x70008 0x7000b >;
			};
			leader_sequence_el_theta {
				bindings = < &uc 0x3b8 0x398 >;
				sequence = < 0x70008 0x70019 >;
			};
			leader_sequence_el_iota {
				bindings = < &uc 0x3b9 0x399 >;
				sequence = < 0x70008 0x7000c >;
			};
			leader_sequence_el_kappa {
				bindings = < &uc 0x3ba 0x39a >;
				sequence = < 0x70008 0x7000e >;
			};
			leader_sequence_el_lambda {
				bindings = < &uc 0x3bb 0x39b >;
				sequence = < 0x70008 0x7000f >;
			};
			leader_sequence_el_mu {
				bindings = < &uc 0x3bc 0x39c >;
				sequence = < 0x70008 0x70010 >;
			};
			leader_sequence_el_nu {
				bindings = < &uc 0x3bd 0x39d >;
				sequence = < 0x70008 0x70011 >;
			};
			leader_sequence_el_xi {
				bindings = < &uc 0x3be 0x39e >;
				sequence = < 0x70008 0x7001b >;
			};
			leader_sequence_el_omikron {
				bindings = < &uc 0x3bf 0x39f >;
				sequence = < 0x70008 0x70012 >;
			};
			leader_sequence_el_pi {
				bindings = < &uc 0x3c0 0x3a0 >;
				sequence = < 0x70008 0x70013 >;
			};
			leader_sequence_el_rho {
				bindings = < &uc 0x3c1 0x3a1 >;
				sequence = < 0x70008 0x70015 >;
			};
			leader_sequence_el_sigma {
				bindings = < &uc 0x3c3 0x3a3 >;
				sequence = < 0x70008 0x70016 >;
			};
			leader_sequence_el_tau {
				bindings = < &uc 0x3c4 0x3a4 >;
				sequence = < 0x70008 0x70017 >;
			};
			leader_sequence_el_upsilon {
				bindings = < &uc 0x3c5 0x3a5 >;
				sequence = < 0x70008 0x70018 >;
			};
			leader_sequence_el_phi {
				bindings = < &uc 0x3d5 0x3a6 >;
				sequence = < 0x70008 0x70009 >;
			};
			leader_sequence_el_chi {
				bindings = < &uc 0x3c7 0x3a7 >;
				sequence = < 0x70008 0x70006 >;
			};
			leader_sequence_el_psi {
				bindings = < &uc 0x3c8 0x3a8 >;
				sequence = < 0x70008 0x7001c >;
			};
			leader_sequence_el_omega {
				bindings = < &uc 0x3c9 0x3a9 >;
				sequence = < 0x70008 0x7001a >;
			};
			leader_sequence_usb {
				bindings = < &out 0x1 >;
				sequence = < 0x70018 0x70016 0x70005 >;
			};
			leader_sequence_ble {
				bindings = < &out 0x2 >;
				sequence = < 0x70005 0x7000f 0x70008 >;
			};
			leader_sequence_reset {
				bindings = < &sys_reset >;
				sequence = < 0x70015 0x70008 0x70016 0x70008 0x70017 >;
			};
			leader_sequence_boot {
				bindings = < &bootloader >;
				sequence = < 0x70005 0x70012 0x70012 0x70017 >;
			};
		};
		mt_home: mt_home {
			compatible = "zmk,behavior-hold-tap";
			#binding-cells = < 0x2 >;
			bindings = < &masked_home >, < &kp >;
			flavor = "tap-preferred";
			tapping-term-ms = < 0xdc >;
			quick-tap-ms = < 0xdc >;
			hold-trigger-key-positions = < 0x0 >;
			phandle = < 0x48 >;
		};
		mt_end: mt_end {
			compatible = "zmk,behavior-hold-tap";
			#binding-cells = < 0x2 >;
			bindings = < &masked_end >, < &kp >;
			flavor = "tap-preferred";
			tapping-term-ms = < 0xdc >;
			quick-tap-ms = < 0xdc >;
			hold-trigger-key-positions = < 0x0 >;
			phandle = < 0x49 >;
		};
		masked_home: masked_home {
			compatible = "zmk,behavior-mod-morph";
			#binding-cells = < 0x0 >;
			bindings = < &kp 0x7004a >, < &kp 0x7004a >;
			mods = < 0x1 >;
			phandle = < 0x19 >;
		};
		masked_end: masked_end {
			compatible = "zmk,behavior-mod-morph";
			#binding-cells = < 0x0 >;
			bindings = < &kp 0x7004d >, < &kp 0x7004d >;
			mods = < 0x1 >;
			phandle = < 0x1a >;
		};
		magic_shift: magic_shift {
			compatible = "zmk,behavior-hold-tap";
			#binding-cells = < 0x2 >;
			bindings = < &kp >, < &magic_shift_tap >;
			flavor = "balanced";
			tapping-term-ms = < 0xc8 >;
			quick-tap-ms = < 0xaf >;
			phandle = < 0x2d >;
		};
		magic_shift_tap: magic_shift_tap {
			compatible = "zmk,behavior-mod-morph";
			#binding-cells = < 0x0 >;
			bindings = < &shift_repeat >, < &caps_word >;
			mods = < 0x2 >;
			phandle = < 0x1b >;
		};
		shift_repeat: shift_repeat {
			compatible = "zmk,behavior-adaptive-key";
			#binding-cells = < 0x0 >;
			bindings = < &sk 0x700e1 >;
			phandle = < 0x1c >;
			repeat {
				trigger-keys = < 0x70004 0x70005 0x70006 0x70007 0x70008 0x70009 0x7000a 0x7000b 0x7000c 0x7000d 0x7000e 0x7000f 0x70010 0x70011 0x70012 0x70013 0x70014 0x70015 0x70016 0x70017 0x70018 0x70019 0x7001a 0x7001b 0x7001c 0x7001d >;
				bindings = < &key_repeat >;
				max-prior-idle-ms = < 0x4b0 >;
				strict-modifiers;
			};
		};
		smart_num: smart_num {
			compatible = "zmk,behavior-hold-tap";
			#binding-cells = < 0x2 >;
			bindings = < &mo >, < &num_dance >;
			flavor = "balanced";
			tapping-term-ms = < 0xc8 >;
			quick-tap-ms = < 0xaf >;
		};
		num_dance: num_dance {
			compatible = "zmk,behavior-tap-dance";
			#binding-cells = < 0x0 >;
			bindings = < &num_word 0x3 >, < &sl 0x3 >;
			tapping-term-ms = < 0xc8 >;
			phandle = < 0x20 >;
		};
		smart_mouse: smart_mouse {
			compatible = "zmk,behavior-tri-state";
			#binding-cells = < 0x0 >;
			bindings = < &tog 0x5 >, < &none >, < &tog 0x5 >;
			ignored-key-positions = < 0x3 0x2 0x1f 0x1e 0x6 0x7 0x8 0xf 0x10 0x11 0x12 0x13 0x1a 0x1b 0x1c 0x20 0x21 >;
			ignored-layers = < 0x5 0x1 0x2 >;
			phandle = < 0x34 >;
		};
		comma_morph: comma_morph {
			compatible = "zmk,behavior-mod-morph";
			#binding-cells = < 0x0 >;
			mods = < 0x22 >;
			bindings = < &kp 0x70036 >, < &comma_inner_morph >;
			phandle = < 0x41 >;
		};
		comma_inner_morph: comma_inner_morph {
			compatible = "zmk,behavior-mod-morph";
			#binding-cells = < 0x0 >;
			mods = < 0x11 >;
			bindings = < &kp 0x70033 >, < &kp 0x2070036 >;
			phandle = < 0x25 >;
		};
		dot_morph: dot_morph {
			compatible = "zmk,behavior-mod-morph";
			#binding-cells = < 0x0 >;
			mods = < 0x22 >;
			bindings = < &kp 0x70037 >, < &dot_inner_morph >;
			phandle = < 0x42 >;
		};
		dot_inner_morph: dot_inner_morph {
			compatible = "zmk,behavior-mod-morph";
			#binding-cells = < 0x0 >;
			mods = < 0x11 >;
			bindings = < &kp 0x2070033 >, < &kp 0x2070037 >;
			phandle = < 0x26 >;
		};
		qexcl: qexcl {
			compatible = "zmk,behavior-mod-morph";
			#binding-cells = < 0x0 >;
			mods = < 0x22 >;
			bindings = < &kp 0x2070038 >, < &kp 0x207001e >;
			phandle = < 0x43 >;
		};
		lpar_lt: lpar_lt {
			compatible = "zmk,behavior-mod-morph";
			#binding-cells = < 0x0 >;
			mods = < 0x22 >;
			bindings = < &kp 0x2070026 >, < &kp 0x2070036 >;
			phandle = < 0x13 >;
		};
		rpar_gt: rpar_gt {
			compatible = "zmk,behavior-mod-morph";
			#binding-cells = < 0x0 >;
			mods = < 0x22 >;
			bindings = < &kp 0x2070027 >, < &kp 0x2070037 >;
			phandle = < 0x14 >;
		};
		lt_spc: lt_spc {
			compatible = "zmk,behavior-hold-tap";
			#binding-cells = < 0x2 >;
			bindings = < &mo >, < &spc_morph >;
			flavor = "balanced";
			tapping-term-ms = < 0xc8 >;
			quick-tap-ms = < 0xaf >;
		};
		spc_morph: spc_morph {
			compatible = "zmk,behavior-mod-morph";
			#binding-cells = < 0x0 >;
			mods = < 0x22 >;
			bindings = < &kp 0x7002c >, < &dot_spc >;
			phandle = < 0x27 >;
		};
		dot_spc: dot_spc {
			compatible = "zmk,behavior-macro";
			#binding-cells = < 0x0 >;
			bindings = < &kp 0x70037 &kp 0x7002c &sk 0x700e1 >;
			wait-ms = < 0x0 >;
			tap-ms = < 0x5 >;
			phandle = < 0x28 >;
		};
		bs_del: bs_del {
			compatible = "zmk,behavior-mod-morph";
			#binding-cells = < 0x0 >;
			bindings = < &kp 0x7002a >, < &kp 0x7004c >;
			mods = < 0x22 >;
			keep-mods = < 0x20 >;
		};
		copy_cut: copy_cut {
			compatible = "zmk,behavior-tap-dance";
			#binding-cells = < 0x0 >;
			bindings = < &kp 0x1070049 >, < &kp 0x107001b >;
			tapping-term-ms = < 0xc8 >;
		};
		leader_sft: leader_sft {
			compatible = "zmk,behavior-macro";
			#binding-cells = < 0x0 >;
			bindings = < &sk 0x700e1 &leader >;
			phandle = < 0x12 >;
		};
		bt_win: bt_win {
			compatible = "zmk,behavior-macro";
			#binding-cells = < 0x0 >;
			bindings = < &bt 0x3 0x0 >, < &os_sel 0x0 >;
			wait-ms = < 0xa >;
			tap-ms = < 0x5 >;
		};
		bt_mac: bt_mac {
			compatible = "zmk,behavior-macro";
			#binding-cells = < 0x0 >;
			bindings = < &bt 0x3 0x1 >, < &os_sel 0x1 >;
			wait-ms = < 0xa >;
			tap-ms = < 0x5 >;
		};
		bt_lin: bt_lin {
			compatible = "zmk,behavior-macro";
			#binding-cells = < 0x0 >;
			bindings = < &bt 0x3 0x2 >, < &os_sel 0x2 >;
			wait-ms = < 0xa >;
			tap-ms = < 0x5 >;
		};
		ok_swp_mod: os_key_swapper_mod {
			compatible = "zmk,behavior-os-key";
			#binding-cells = < 0x0 >;
			bindings = < &kt 0x700e2 >, < &kt 0x700e3 >, < &kt 0x700e2 >;
			phandle = < 0x2c >;
		};
		swapper: swapper {
			compatible = "zmk,behavior-tri-state";
			#binding-cells = < 0x0 >;
			bindings = < &ok_swp_mod >, < &kp 0x7002b >, < &ok_swp_mod >;
			ignored-key-positions = < 0x2 0x7 0x10 0x11 0x12 >;
			phandle = < 0x47 >;
		};
		esc_magic_hold: esc_magic_hold {
			compatible = "zmk,behavior-macro";
			#binding-cells = < 0x0 >;
			bindings = < &magic_shift 0x700e1 0x0 >;
			wait-ms = < 0x0 >;
			tap-ms = < 0x5 >;
			phandle = < 0x2e >;
		};
		esc_magic: esc_magic {
			compatible = "zmk,behavior-hold-tap";
			#binding-cells = < 0x2 >;
			bindings = < &esc_magic_hold >, < &kp >;
			flavor = "balanced";
			tapping-term-ms = < 0xc8 >;
			quick-tap-ms = < 0xaf >;
		};
		esc_sym: esc_sym {
			compatible = "zmk,behavior-hold-tap";
			#binding-cells = < 0x2 >;
			bindings = < &mo >, < &kp >;
			flavor = "balanced";
			tapping-term-ms = < 0xc8 >;
			quick-tap-ms = < 0xaf >;
			phandle = < 0x44 >;
		};
		j_tab: j_tab {
			compatible = "zmk,behavior-hold-tap";
			#binding-cells = < 0x2 >;
			bindings = < &kp >, < &kp >;
			flavor = "balanced";
			tapping-term-ms = < 0xc8 >;
			quick-tap-ms = < 0xaf >;
			phandle = < 0x3f >;
		};
		magic_sym: magic_sym {
			compatible = "zmk,behavior-hold-tap";
			#binding-cells = < 0x2 >;
			bindings = < &mo >, < &sl >;
			flavor = "balanced";
			tapping-term-ms = < 0xc8 >;
			quick-tap-ms = < 0xaf >;
			phandle = < 0x3d >;
		};
	};
	mkp_input_listener: mkp_input_listener {
		compatible = "zmk,input-listener";
		device = < &mkp >;
	};
	mmv_input_listener: mmv_input_listener {
		compatible = "zmk,input-listener";
		device = < &mmv >;
		warp {
			layers = < 0x1 >;
			input-processors = < &zip_xy_scaler 0x3 0x1 >;
		};
		precision {
			layers = < 0x2 >;
			input-processors = < &zip_xy_scaler 0x1 0x2 >;
		};
	};
	msc_input_listener: msc_input_listener {
		compatible = "zmk,input-listener";
		device = < &msc >;
		warp {
			layers = < 0x1 >;
			input-processors = < &zip_scroll_scaler 0x2 0x1 >;
		};
		precision {
			layers = < 0x2 >;
			input-processors = < &zip_scroll_scaler 0x1 0x2 >;
		};
	};
	combos {
		compatible = "zmk,combos";
		combo_esc {
			timeout-ms = < 0x12 >;
			bindings = < &kp 0x70029 >;
			key-positions = < 0x1 0x2 >;
			layers = < 0x0 0x1 0x3 >;
			require-prior-idle-ms = < 0x96 >;
		};
		combo_mouse {
			timeout-ms = < 0x12 >;
			bindings = < &smart_mouse >;
			key-positions = < 0x2 0x3 >;
			layers = < 0x0 0x1 0x3 >;
			require-prior-idle-ms = < 0x96 >;
		};
		combo_tab {
			timeout-ms = < 0x12 >;
			bindings = < &hml 0x20700e2 0x7002b >;
			key-positions = < 0xb 0xc >;
			layers = < 0x0 0x1 0x3 >;
			require-prior-idle-ms = < 0x96 >;
		};
		combo_ldr {
			timeout-ms = < 0x12 >;
			bindings = < &hm_combo_ldr 0x20700e0 0x0 >;
			key-positions = < 0xc 0xd >;
			layers = < 0x0 0x1 0x3 >;
			require-prior-idle-ms = < 0x96 >;
		};
		combo_ldrsh {
			timeout-ms = < 0x12 >;
			bindings = < &hm_combo_ldrsh 0x30700e2 0x0 >;
			key-positions = < 0xb 0xc 0xd >;
			layers = < 0x0 0x1 0x3 >;
			require-prior-idle-ms = < 0x96 >;
		};
		combo_tmux {
			timeout-ms = < 0x12 >;
			bindings = < &kp 0x1070016 >;
			key-positions = < 0x14 0x15 >;
			layers = < 0x0 0x1 0x3 >;
			require-prior-idle-ms = < 0x96 >;
		};
		combo_cut {
			timeout-ms = < 0x12 >;
			bindings = < &ok_cut >;
			key-positions = < 0x15 0x17 >;
			layers = < 0x0 0x1 0x3 >;
			require-prior-idle-ms = < 0x96 >;
		};
		combo_copy {
			timeout-ms = < 0x12 >;
			bindings = < &ok_copy >;
			key-positions = < 0x15 0x16 >;
			layers = < 0x0 0x1 0x3 >;
			require-prior-idle-ms = < 0x96 >;
		};
		combo_paste {
			timeout-ms = < 0x12 >;
			bindings = < &ok_paste >;
			key-positions = < 0x16 0x17 >;
			layers = < 0x0 0x1 0x3 >;
			require-prior-idle-ms = < 0x96 >;
		};
		combo_bspc {
			timeout-ms = < 0x12 >;
			bindings = < &kp 0x7002a >;
			key-positions = < 0x6 0x7 >;
			layers = < 0x0 0x1 0x3 >;
			require-prior-idle-ms = < 0x96 >;
		};
		combo_del {
			timeout-ms = < 0x12 >;
			bindings = < &kp 0x7004c >;
			key-positions = < 0x7 0x8 >;
			layers = < 0x0 0x1 0x3 >;
			require-prior-idle-ms = < 0x96 >;
		};
		combo_lpar {
			timeout-ms = < 0x12 >;
			bindings = < &hm_combo_lpar 0x200700e0 0x0 >;
			key-positions = < 0x10 0x11 >;
			layers = < 0x0 0x3 >;
			require-prior-idle-ms = < 0x96 >;
		};
		combo_rpar {
			timeout-ms = < 0x12 >;
			bindings = < &hm_combo_rpar 0x200700e2 0x0 >;
			key-positions = < 0x11 0x12 >;
			layers = < 0x0 0x3 >;
			require-prior-idle-ms = < 0x96 >;
		};
		combo_lt {
			timeout-ms = < 0x12 >;
			bindings = < &kp 0x2070036 >;
			key-positions = < 0x10 0x11 >;
			layers = < 0x1 >;
			require-prior-idle-ms = < 0x96 >;
		};
		combo_gt {
			timeout-ms = < 0x12 >;
			bindings = < &kp 0x2070037 >;
			key-positions = < 0x11 0x12 >;
			layers = < 0x1 >;
			require-prior-idle-ms = < 0x96 >;
		};
		combo_lbkt {
			timeout-ms = < 0x12 >;
			bindings = < &kp 0x7002f >;
			key-positions = < 0x1a 0x1b >;
			layers = < 0x0 0x3 >;
			require-prior-idle-ms = < 0x96 >;
		};
		combo_rbkt {
			timeout-ms = < 0x12 >;
			bindings = < &kp 0x70030 >;
			key-positions = < 0x1b 0x1c >;
			layers = < 0x0 0x3 >;
			require-prior-idle-ms = < 0x96 >;
		};
		combo_lbrc {
			timeout-ms = < 0x12 >;
			bindings = < &kp 0x207002f >;
			key-positions = < 0x1a 0x1b >;
			layers = < 0x1 >;
			require-prior-idle-ms = < 0x96 >;
		};
		combo_rbrc {
			timeout-ms = < 0x12 >;
			bindings = < &kp 0x2070030 >;
			key-positions = < 0x1b 0x1c >;
			layers = < 0x1 >;
			require-prior-idle-ms = < 0x96 >;
		};
		combo_at {
			timeout-ms = < 0x1e >;
			bindings = < &kp 0x207001f >;
			key-positions = < 0x1 0xb >;
			layers = < 0x0 0x1 0x3 >;
			require-prior-idle-ms = < 0x32 >;
		};
		combo_hash {
			timeout-ms = < 0x1e >;
			bindings = < &kp 0x2070020 >;
			key-positions = < 0x2 0xc >;
			layers = < 0x0 0x1 0x3 >;
			require-prior-idle-ms = < 0x32 >;
		};
		combo_dllr {
			timeout-ms = < 0x1e >;
			bindings = < &kp 0x2070021 >;
			key-positions = < 0x3 0xd >;
			layers = < 0x0 0x1 0x3 >;
			require-prior-idle-ms = < 0x32 >;
		};
		combo_prcnt {
			timeout-ms = < 0x1e >;
			bindings = < &kp 0x2070022 >;
			key-positions = < 0x4 0xe >;
			layers = < 0x0 0x1 0x3 >;
			require-prior-idle-ms = < 0x32 >;
		};
		combo_grave {
			timeout-ms = < 0x1e >;
			bindings = < &kp 0x70035 >;
			key-positions = < 0xb 0x15 >;
			layers = < 0x0 0x1 0x3 >;
			require-prior-idle-ms = < 0x32 >;
		};
		combo_bslh {
			timeout-ms = < 0x1e >;
			bindings = < &kp 0x70031 >;
			key-positions = < 0xc 0x16 >;
			layers = < 0x0 0x1 0x3 >;
			require-prior-idle-ms = < 0x32 >;
		};
		combo_equal {
			timeout-ms = < 0x1e >;
			bindings = < &kp 0x7002e >;
			key-positions = < 0xd 0x17 >;
			layers = < 0x0 0x1 0x3 >;
			require-prior-idle-ms = < 0x32 >;
		};
		combo_tilde {
			timeout-ms = < 0x1e >;
			bindings = < &kp 0x2070035 >;
			key-positions = < 0xe 0x18 >;
			layers = < 0x0 0x1 0x3 >;
			require-prior-idle-ms = < 0x32 >;
		};
		combo_caret {
			timeout-ms = < 0x1e >;
			bindings = < &kp 0x2070023 >;
			key-positions = < 0x5 0xf >;
			layers = < 0x0 0x1 0x3 >;
			require-prior-idle-ms = < 0x32 >;
		};
		combo_plus {
			timeout-ms = < 0x1e >;
			bindings = < &kp 0x207002e >;
			key-positions = < 0x6 0x10 >;
			layers = < 0x0 0x1 0x3 >;
			require-prior-idle-ms = < 0x32 >;
		};
		combo_star {
			timeout-ms = < 0x1e >;
			bindings = < &kp 0x2070025 >;
			key-positions = < 0x7 0x11 >;
			layers = < 0x0 0x1 0x3 >;
			require-prior-idle-ms = < 0x32 >;
		};
		combo_amps {
			timeout-ms = < 0x1e >;
			bindings = < &kp 0x2070024 >;
			key-positions = < 0x8 0x12 >;
			layers = < 0x0 0x1 0x3 >;
			require-prior-idle-ms = < 0x32 >;
		};
		combo_under {
			timeout-ms = < 0x1e >;
			bindings = < &kp 0x207002d >;
			key-positions = < 0xf 0x19 >;
			layers = < 0x0 0x1 0x3 >;
			require-prior-idle-ms = < 0x32 >;
		};
		combo_minus {
			timeout-ms = < 0x1e >;
			bindings = < &kp 0x7002d >;
			key-positions = < 0x10 0x1a >;
			layers = < 0x0 0x1 0x3 >;
			require-prior-idle-ms = < 0x32 >;
		};
		combo_fslh {
			timeout-ms = < 0x1e >;
			bindings = < &kp 0x70038 >;
			key-positions = < 0x11 0x1b >;
			layers = < 0x0 0x1 0x3 >;
			require-prior-idle-ms = < 0x32 >;
		};
		combo_pipe {
			timeout-ms = < 0x1e >;
			bindings = < &kp 0x2070031 >;
			key-positions = < 0x12 0x1c >;
			layers = < 0x0 0x1 0x3 >;
			require-prior-idle-ms = < 0x32 >;
		};
		combo_magic_sym {
			timeout-ms = < 0x12 >;
			key-positions = < 0x8 0x9 >;
			bindings = < &magic_sym 0x6 0x6 >;
			layers = < 0x0 >;
		};
	};
	zip_xy_scaler: zip_xy_scaler {
		compatible = "zmk,input-processor-scaler";
		#input-processor-cells = < 0x2 >;
		type = < 0x2 >;
		codes = < 0x0 0x1 >;
		track-remainders;
		phandle = < 0x31 >;
	};
	zip_scroll_scaler: zip_scroll_scaler {
		compatible = "zmk,input-processor-scaler";
		#input-processor-cells = < 0x2 >;
		type = < 0x2 >;
		codes = < 0x8 0x6 >;
		track-remainders;
		phandle = < 0x33 >;
	};
	zip_button_behaviors: zip_button_behaviors {
		compatible = "zmk,input-processor-behaviors";
		#input-processor-cells = < 0x0 >;
		codes = < 0x100 0x101 0x102 >;
		bindings = < &none &none &none >;
	};
	conditional_layers {
		compatible = "zmk,conditional-layers";
		tri_layer_sys {
			if-layers = < 0x2 0x3 >;
			then-layer = < 0x4 >;
		};
	};
	keymap {
		compatible = "zmk,keymap";
		layer_Base {
			display-name = "Base";
			bindings = < &kp 0x70014 &kp 0x7001a &kp 0x70008 &kp 0x70015 &kp 0x70017 &kp 0x7001c &kp 0x70018 &kp 0x7000c &kp 0x70012 &kp 0x70013 &hml 0x700e0 0x70004 &hml 0x700e2 0x70016 &hml 0x700e3 0x70007 &lt 0x1 0x70009 &kp 0x7000a &kp 0x7000b &j_tab 0x7002b 0x7000d &hmr 0x700e3 0x7000e &hmr 0x700e6 0x7000f &hmr 0x700e4 0x70033 &kp 0x7001d &kp 0x7001b &kp 0x70006 &kp 0x70019 &kp 0x70005 &kp 0x70011 &kp 0x70010 &comma_morph &dot_morph &qexcl &esc_sym 0x6 0x70029 &mt 0x700e1 0x7002c &lt 0x2 0x70028 &lt 0x3 0x7002a >;
		};
		layer_Nav {
			display-name = "Nav";
			bindings = < &kp 0x407003d &trans &kp 0x207002b &swapper &trans &kp 0x7004b &mt 0x107002a 0x7002a &mt 0x107004a 0x70052 &mt 0x107004c 0x7004c &swapper &sk 0x700e3 &sk 0x700e2 &sk 0x700e1 &sk 0x700e0 &trans &kp 0x7004e &mt_home 0x0 0x70050 &mt 0x107004d 0x70051 &mt_end 0x0 0x7004f &kp 0x70028 &ok_undo &ok_redo &trans &trans &trans &kp 0x70049 &kp 0x7002b &trans &trans &trans &trans &trans &swapper &kp 0x7009b >;
		};
		layer_Fn {
			display-name = "Fn";
			bindings = < &kp 0x70045 &kp 0x70040 &kp 0x70041 &kp 0x70042 &trans &trans &kp 0xc00b6 &kp 0xc00e9 &kp 0xc00b5 &trans &hml 0x700e3 0x70044 &hml 0x700e2 0x7003d &hml 0x700e1 0x7003e &hml 0x700e0 0x7003f &trans &trans &hmr 0x700e0 0x9070050 &hmr 0x700e5 0xc00ea &hmr 0x700e2 0x907004f &trans &kp 0x70043 &kp 0x7003a &kp 0x7003b &kp 0x7003c &trans &kp 0xb070004 &kp 0xb070014 &kp 0x4070035 &trans &trans &trans &trans &kp 0xc00e2 &kp 0xc00cd >;
		};
		layer_Num {
			display-name = "Num";
			bindings = < &trans &kp 0x70024 &kp 0x70025 &kp 0x70026 &trans &trans &trans &trans &trans &trans &hml 0x700e3 0x70027 &hml 0x700e2 0x70021 &hml 0x700e1 0x70022 &hml 0x700e0 0x70023 &trans &trans &trans &trans &trans &trans &trans &kp 0x7001e &kp 0x7001f &kp 0x70020 &trans &trans &trans &trans &trans &trans &trans &trans &trans &trans >;
		};
		layer_Sys {
			display-name = "Sys";
			bindings = < &os_sel 0x0 &os_sel 0x1 &os_sel 0x2 &trans &trans &out 0x1 &out 0x2 &trans &trans &trans &bt 0x3 0x0 &bt 0x3 0x1 &bt 0x3 0x2 &bt 0x3 0x3 &bt 0x0 0x0 &bootloader &trans &trans &trans &trans &studio_unlock &trans &trans &trans &sys_reset &sys_reset &trans &trans &trans &trans &trans &trans &trans &trans >;
		};
		layer_Mouse {
			display-name = "Mouse";
			bindings = < &trans &trans &trans &trans &trans &trans &kp 0x7004b &mmv 0xfda8 &kp 0x7004e &trans &trans &trans &trans &trans &trans &msc 0xffec0000 &mmv 0xfda80000 &mmv 0x258 &mmv 0x2580000 &msc 0x140000 &trans &trans &trans &trans &trans &trans &mkp 0x1 &mkp 0x4 &mkp 0x2 &trans &trans &trans &msc 0x14 &msc 0xffec >;
		};
		layer_Sym {
			display-name = "Sym";
			bindings = < &kp 0x207002f &kp 0x2070024 &kp 0x2070025 &kp 0x2070026 &kp 0x2070030 &kp 0x70023 &kp 0x70024 &kp 0x70025 &kp 0x70026 &kp 0x70027 &kp 0x70034 &kp 0x2070021 &kp 0x2070022 &kp 0x2070023 &kp 0x207002e &kp 0x2070034 &kp 0x2070038 &kp 0x70034 &kp 0x7002d &kp 0x2070025 &trans &kp 0x2070035 &kp 0x207001e &kp 0x207001f &kp 0x2070020 &kp 0x2070031 &kp 0x207002d &kp 0x207001e &kp 0x2070034 &kp 0x207002e &trans &kp 0x2070026 &kp 0x2070030 &kp 0x70038 >;
		};
	};
};
